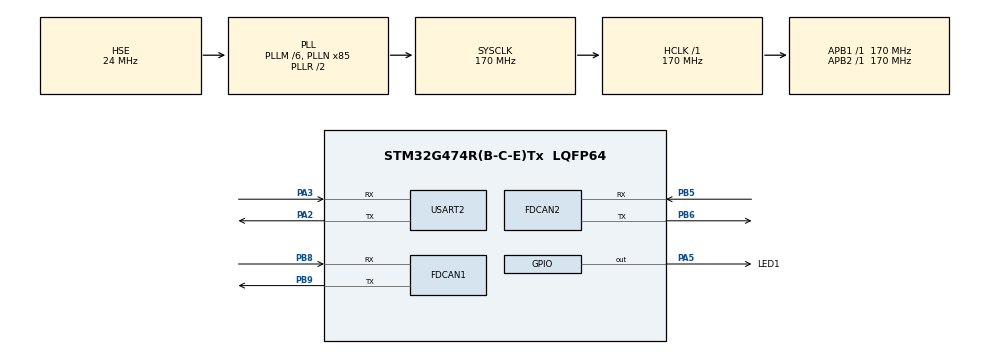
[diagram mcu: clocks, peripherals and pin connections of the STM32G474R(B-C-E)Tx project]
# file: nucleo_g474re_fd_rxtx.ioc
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FDCAN1.AutoRetransmission=ENABLE
FDCAN1.CalculateBaudRateNominal=499999
FDCAN1.CalculateTimeBitNominal=2000
FDCAN1.CalculateTimeQuantumNominal=58.82352941176471
FDCAN1.DataPrescaler=5
FDCAN1.DataSyncJumpWidth=4
FDCAN1.DataTimeSeg1=12
FDCAN1.DataTimeSeg2=4
FDCAN1.FrameFormat=FDCAN_FRAME_FD_BRS
FDCAN1.NominalPrescaler=10
FDCAN1.NominalSyncJumpWidth=6
FDCAN1.NominalTimeSeg1=27
FDCAN1.NominalTimeSeg2=6
FDCAN2.AutoRetransmission=ENABLE
FDCAN2.CalculateBaudRateNominal=499999
FDCAN2.CalculateTimeBitNominal=2000
FDCAN2.CalculateTimeQuantumNominal=58.82352941176471
FDCAN2.DataPrescaler=5
FDCAN2.DataSyncJumpWidth=4
FDCAN2.DataTimeSeg1=12
FDCAN2.DataTimeSeg2=4
FDCAN2.FrameFormat=FDCAN_FRAME_FD_BRS
FDCAN2.NominalPrescaler=10
FDCAN2.NominalSyncJumpWidth=6
FDCAN2.NominalTimeSeg1=27
FDCAN2.NominalTimeSeg2=6
Mcu.Family=STM32G4
Mcu.Name=STM32G474R(B-C-E)Tx
Mcu.Package=LQFP64
NVIC.FDCAN1_IT0_IRQn=true\:0\:0\:false\:false\:true\:true\:true\:true
NVIC.FDCAN1_IT1_IRQn=true\:0\:0\:false\:false\:true\:true\:true\:true
NVIC.FDCAN2_IT0_IRQn=true\:0\:0\:false\:false\:true\:true\:true\:true
NVIC.FDCAN2_IT1_IRQn=true\:0\:0\:false\:false\:true\:true\:true\:true
NVIC.PriorityGroup=NVIC_PRIORITYGROUP_4
PA2.Mode=Asynchronous
PA2.Signal=USART2_TX
PA3.Mode=Asynchronous
PA3.Signal=USART2_RX
PA5.GPIO_Label=LED1
PA5.Signal=GPIO_Output
PB5.Mode=FDCAN_Activate
PB5.Signal=FDCAN2_RX
PB6.Mode=FDCAN_Activate
PB6.Signal=FDCAN2_TX
PB8-BOOT0.Mode=FDCAN_Activate
PB8-BOOT0.Signal=FDCAN1_RX
PB9.Mode=FDCAN_Activate
PB9.Signal=FDCAN1_TX
PF0-OSC_IN.Mode=HSE-External-Oscillator
PF0-OSC_IN.Signal=RCC_OSC_IN
PF1-OSC_OUT.Mode=HSE-External-Oscillator
PF1-OSC_OUT.Signal=RCC_OSC_OUT
ProjectManager.HeapSize=0x200
ProjectManager.StackSize=0x400
ProjectManager.TargetToolchain=STM32CubeIDE
RCC.ADC12Freq_Value=170000000
RCC.ADC345Freq_Value=170000000
RCC.AHBFreq_Value=170000000
RCC.APB1Freq_Value=170000000
RCC.APB1TimFreq_Value=170000000
RCC.APB2Freq_Value=170000000
RCC.APB2TimFreq_Value=170000000
RCC.CortexFreq_Value=170000000
RCC.EXTERNAL_CLOCK_VALUE=12288000
RCC.HCLKFreq_Value=170000000
RCC.HSE_VALUE=24000000
RCC.HSI48_VALUE=48000000
RCC.HSI_VALUE=16000000
RCC.LSE_VALUE=32768
RCC.PLLM=RCC_PLLM_DIV6
RCC.PLLN=85
RCC.PLLSourceVirtual=RCC_PLLSOURCE_HSE
RCC.SYSCLKFreq_VALUE=170000000
RCC.SYSCLKSource=RCC_SYSCLKSOURCE_PLLCLK
RCC.USBFreq_Value=170000000
RCC.VCOOutputFreq_Value=340000000
USART2.VirtualMode-Asynchronous=VM_ASYNC
VP_SYS_VS_DBSignals.Mode=DisableDeadBatterySignals
board=custom

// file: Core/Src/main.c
/* USER CODE BEGIN Header */
/**
  ******************************************************************************
  * @file           : main.c
  * @brief          : Main program body
  ******************************************************************************
  * @attention
  *
  * Copyright (c) 2026 STMicroelectronics.
  * All rights reserved.
  *
  * This software is licensed under terms that can be found in the LICENSE file
  * in the root directory of this software component.
  * If no LICENSE file comes with this software, it is provided AS-IS.
  *
  ******************************************************************************
  */
/* USER CODE END Header */
#include "main.h"
#include "fdcan.h"
#include "usart.h"
#include "gpio.h"

/* USER CODE BEGIN Includes */
#include "logs.h"
#include "can_app.h"
/* USER CODE END Includes */

void SystemClock_Config(void);

int main(void)
{

  /* MCU Configuration--------------------------------------------------------*/

  /* Reset of all peripherals, Initializes the Flash interface and the Systick. */
  HAL_Init();

  /* Configure the system clock */
  SystemClock_Config();

  /* Initialize all configured peripherals */
  MX_GPIO_Init();
  MX_USART2_UART_Init();
  MX_FDCAN1_Init();
  MX_FDCAN2_Init();
  /* USER CODE BEGIN 2 */

  can_app_init();
  /* USER CODE END 2 */

  /* Infinite loop */
  /* USER CODE BEGIN WHILE */
  while (1)
  {
//	  HAL_GPIO_TogglePin(LED1_GPIO_Port, LED1_Pin);
//	  LOG_WriteLine("Start");
//	  HAL_Delay(1000);
	  can_app_poll();

    /* USER CODE END WHILE */

  }
}

void SystemClock_Config(void)
{
  RCC_OscInitTypeDef RCC_OscInitStruct = {0};
  RCC_ClkInitTypeDef RCC_ClkInitStruct = {0};

  /** Configure the main internal regulator output voltage
  */
  HAL_PWREx_ControlVoltageScaling(PWR_REGULATOR_VOLTAGE_SCALE1_BOOST);

  /** Initializes the RCC Oscillators according to the specified parameters
  * in the RCC_OscInitTypeDef structure.
  */
  RCC_OscInitStruct.OscillatorType = RCC_OSCILLATORTYPE_HSE;
  RCC_OscInitStruct.HSEState = RCC_HSE_ON;
  RCC_OscInitStruct.PLL.PLLState = RCC_PLL_ON;
  RCC_OscInitStruct.PLL.PLLSource = RCC_PLLSOURCE_HSE;
  RCC_OscInitStruct.PLL.PLLM = RCC_PLLM_DIV6;
  RCC_OscInitStruct.PLL.PLLN = 85;
  RCC_OscInitStruct.PLL.PLLP = RCC_PLLP_DIV2;
  RCC_OscInitStruct.PLL.PLLQ = RCC_PLLQ_DIV2;
  RCC_OscInitStruct.PLL.PLLR = RCC_PLLR_DIV2;
  if (HAL_RCC_OscConfig(&RCC_OscInitStruct) != HAL_OK)
  {
    Error_Handler();
  }

  /** Initializes the CPU, AHB and APB buses clocks
  */
  RCC_ClkInitStruct.ClockType = RCC_CLOCKTYPE_HCLK|RCC_CLOCKTYPE_SYSCLK
                              |RCC_CLOCKTYPE_PCLK1|RCC_CLOCKTYPE_PCLK2;
  RCC_ClkInitStruct.SYSCLKSource = RCC_SYSCLKSOURCE_PLLCLK;
  RCC_ClkInitStruct.AHBCLKDivider = RCC_SYSCLK_DIV1;
  RCC_ClkInitStruct.APB1CLKDivider = RCC_HCLK_DIV1;
  RCC_ClkInitStruct.APB2CLKDivider = RCC_HCLK_DIV1;

  if (HAL_RCC_ClockConfig(&RCC_ClkInitStruct, FLASH_LATENCY_4) != HAL_OK)
  {
    Error_Handler();
  }
}

void Error_Handler(void)
{
  __disable_irq();
  while (1)
  {
  }
}
